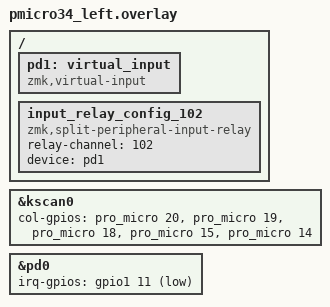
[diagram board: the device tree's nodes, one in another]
/*
 * Copyright (c) 2020 Pete Johanson
 *
 * SPDX-License-Identifier: MIT
 */

#include "pmicro34.dtsi"

&kscan0 {
	col-gpios
		= <&pro_micro 20 GPIO_ACTIVE_HIGH>
		, <&pro_micro 19 GPIO_ACTIVE_HIGH>
		, <&pro_micro 18 GPIO_ACTIVE_HIGH>
		, <&pro_micro 15 GPIO_ACTIVE_HIGH>
		, <&pro_micro 14 GPIO_ACTIVE_HIGH>
		;
};

#include "pmicro34_trackball.dtsi"

/* enable &pd0 on central. typical input device for zephyr input subsystem. */
/* NOTE 1: use the same device alias (&pd0) on central and peripheral(s) is alright. */
&pd0 {
  status = "okay";
  irq-gpios = <&gpio1 11 (GPIO_ACTIVE_LOW | GPIO_PULL_UP)>;
};

/ {
	/* define virtual input, will be resurrected for emitting input event */
	/* NOTE: set `device = <&pd1>` in `zmk,input-listener` */
	pd1: virtual_input {
		compatible = "zmk,virtual-input";
	};
};

/ {
	/* for central side, define (relay-channel)-to-(virtual-input) mapping */
	input_relay_config_102 {
		compatible = "zmk,split-peripheral-input-relay";
		
		/* channel id, used to filter incoming annotated input event from split peripheral */
		/* NOTE: should matching relay-channel on peripheral overlay */
		relay-channel = <102>;

		/* virtual input device on central, which used to emit input event as an agent device */
		device = <&pd1>;
	};
};

// / {
// 	lra0: haptic_generic_lra {
// 		compatible = "zmk,haptic-generic";
// 		#haptic-binding-cells = <0>;
// 		control-gpios = <&gpio0 5 GPIO_ACTIVE_HIGH>;
// 	};
// };
